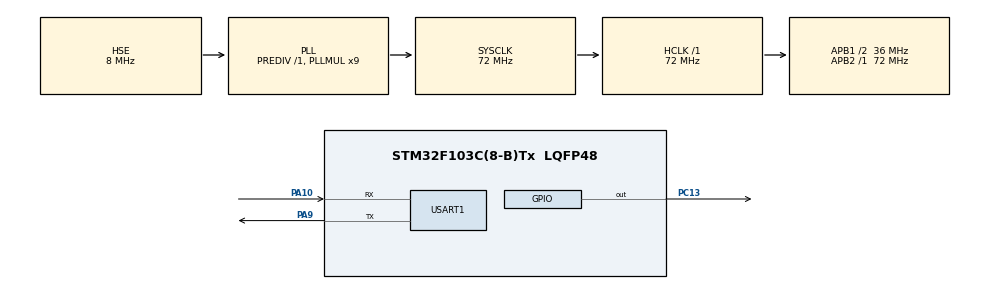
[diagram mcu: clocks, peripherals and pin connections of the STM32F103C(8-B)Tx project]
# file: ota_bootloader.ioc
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Dma.Request0=USART1_RX
Dma.Request1=USART1_TX
Dma.USART1_RX.0.Direction=DMA_PERIPH_TO_MEMORY
Dma.USART1_RX.0.Instance=DMA1_Channel5
Dma.USART1_RX.0.MemDataAlignment=DMA_MDATAALIGN_BYTE
Dma.USART1_RX.0.MemInc=DMA_MINC_ENABLE
Dma.USART1_RX.0.Mode=DMA_NORMAL
Dma.USART1_RX.0.PeriphDataAlignment=DMA_PDATAALIGN_BYTE
Dma.USART1_RX.0.PeriphInc=DMA_PINC_DISABLE
Dma.USART1_RX.0.Priority=DMA_PRIORITY_LOW
Dma.USART1_TX.1.Direction=DMA_MEMORY_TO_PERIPH
Dma.USART1_TX.1.Instance=DMA1_Channel4
Dma.USART1_TX.1.MemDataAlignment=DMA_MDATAALIGN_BYTE
Dma.USART1_TX.1.MemInc=DMA_MINC_ENABLE
Dma.USART1_TX.1.Mode=DMA_NORMAL
Dma.USART1_TX.1.PeriphDataAlignment=DMA_PDATAALIGN_BYTE
Dma.USART1_TX.1.PeriphInc=DMA_PINC_DISABLE
Dma.USART1_TX.1.Priority=DMA_PRIORITY_LOW
Mcu.Family=STM32F1
Mcu.Name=STM32F103C(8-B)Tx
Mcu.Package=LQFP48
NVIC.DMA1_Channel4_IRQn=true\:0\:0\:false\:false\:true\:false\:true
NVIC.DMA1_Channel5_IRQn=true\:0\:0\:false\:false\:true\:false\:true
NVIC.PriorityGroup=NVIC_PRIORITYGROUP_4
PA10.Mode=Asynchronous
PA10.Signal=USART1_RX
PA13.Mode=Serial_Wire
PA13.Signal=SYS_JTMS-SWDIO
PA14.Mode=Serial_Wire
PA14.Signal=SYS_JTCK-SWCLK
PA9.Mode=Asynchronous
PA9.Signal=USART1_TX
PC13-TAMPER-RTC.GPIO_ModeDefaultOutputPP=GPIO_MODE_OUTPUT_PP
PC13-TAMPER-RTC.GPIO_PuPd=GPIO_NOPULL
PC13-TAMPER-RTC.PinState=GPIO_PIN_SET
PC13-TAMPER-RTC.Signal=GPIO_Output
PD0-OSC_IN.Mode=HSE-External-Oscillator
PD0-OSC_IN.Signal=RCC_OSC_IN
PD1-OSC_OUT.Mode=HSE-External-Oscillator
PD1-OSC_OUT.Signal=RCC_OSC_OUT
ProjectManager.HeapSize=0x200
ProjectManager.StackSize=0x400
ProjectManager.TargetToolchain=MDK-ARM V5.27
RCC.AHBFreq_Value=72000000
RCC.APB1CLKDivider=RCC_HCLK_DIV2
RCC.APB1Freq_Value=36000000
RCC.APB1TimFreq_Value=72000000
RCC.APB2Freq_Value=72000000
RCC.APB2TimFreq_Value=72000000
RCC.HCLKFreq_Value=72000000
RCC.PLLMUL=RCC_PLL_MUL9
RCC.PLLSourceVirtual=RCC_PLLSOURCE_HSE
RCC.SYSCLKFreq_VALUE=72000000
RCC.SYSCLKSource=RCC_SYSCLKSOURCE_PLLCLK
RCC.USBFreq_Value=72000000
USART1.VirtualMode=VM_ASYNC
board=custom

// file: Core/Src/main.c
/* USER CODE BEGIN Header */
/**
  ******************************************************************************
  * @file           : main.c
  * @brief          : Main program body
  ******************************************************************************
  * @attention
  *
  * <h2><center>&copy; Copyright (c) 2021 STMicroelectronics.
  * All rights reserved.</center></h2>
  *
  * This software component is licensed by ST under BSD 3-Clause license,
  * the "License"; You may not use this file except in compliance with the
  * License. You may obtain a copy of the License at:
  *                        opensource.org/licenses/BSD-3-Clause
  *
  ******************************************************************************
  */
/* USER CODE END Header */
#include "main.h"
#include "dma.h"
#include "usart.h"
#include "gpio.h"

/* USER CODE BEGIN Includes */
#include "stdio.h"
#include "common.h"
/* USER CODE END Includes */

/* USER CODE BEGIN PD */
#define MAGIC_NUM           0xCAFEBABE
#define MISC_START          0x0800FC00
#define UPDATE_FIRMWARE     0xAAAAAAAA
#define ERASE_FIRMWARE      0xDEADBEEF
/* USER CODE END PD */

void SystemClock_Config(void);

/* USER CODE BEGIN 0 */

void BlinkLed(int n, int delayms)
{
    for (int i = 0; i < n * 2; i++) {
        HAL_GPIO_TogglePin(GPIOC, GPIO_PIN_13);
        HAL_Delay(delayms);
    }
}

int install_firmware()
{
    return 0;
}

uint32_t get_args()
{
    uint32_t PageAddr = MISC_START;
    uint32_t Data;

    Data = *(__IO uint32_t *)(PageAddr+4);
    return Data;
}

int finish_update()
{
    uint32_t PageError = 0;

    FLASH_EraseInitTypeDef My_Flash;
    HAL_FLASH_Unlock();
    My_Flash.TypeErase = FLASH_TYPEERASE_PAGES;
    My_Flash.PageAddress = MISC_START;
    My_Flash.NbPages = 1;
    HAL_FLASHEx_Erase(&My_Flash, &PageError);
    HAL_FLASH_Program(FLASH_TYPEPROGRAM_WORD, MISC_START, MAGIC_NUM);//write magic number
    HAL_FLASH_Lock();
    return 0;
}

int check_misc()
{
    uint32_t PageAddr = MISC_START;
    uint32_t PageError = 0;
    uint32_t data = MAGIC_NUM;

    data = *(__IO uint32_t *)PageAddr;
    printf("read MISC_START :%0X \n", data);

    if (data != MAGIC_NUM)
    {
        printf("check MISC magic number err \n");
        return 1;
    }

    FLASH_EraseInitTypeDef My_Flash;
    HAL_FLASH_Unlock();
    My_Flash.TypeErase = FLASH_TYPEERASE_PAGES;
    My_Flash.PageAddress = PageAddr;
    My_Flash.NbPages = 1;
    HAL_FLASHEx_Erase(&My_Flash, &PageError);
    HAL_FLASH_Program(FLASH_TYPEPROGRAM_WORD, PageAddr, data);
    HAL_FLASH_Lock();

    return 0;
}
/* USER CODE END 0 */

int main(void)
{

    /* MCU Configuration--------------------------------------------------------*/

    /* Reset of all peripherals, Initializes the Flash interface and the Systick. */
    HAL_Init();

    /* Configure the system clock */
    SystemClock_Config();

    /* Initialize all configured peripherals */
    uint32_t BootArg = 0x00000000;
    MX_GPIO_Init();
    MX_DMA_Init();
    MX_USART1_UART_Init();
    /* USER CODE BEGIN 2 */

    BlinkLed(4, 200);
    printf("*****************************\n");
    printf("*                           *\n");
    printf("*         Bootloader        *\n");
    printf("*                           *\n");
    printf("*****************************\n");
    if (check_misc() != 0){
        printf("check misc failed !\n");
    } else {
        BootArg = get_args();
    }

    printf("read misc args: 0x%0X\n", BootArg);
    switch(BootArg) {
        case 0x00000000:
            break;
        case UPDATE_FIRMWARE:
            install_firmware();
            break;
        case ERASE_FIRMWARE:
        default:
            break;
    }
    Main_Menu();
    /* USER CODE END 2 */

    /* Infinite loop */
    /* USER CODE BEGIN WHILE */
    while (1)
    {
        /*should never be here*/
        HAL_GPIO_TogglePin(GPIOC, GPIO_PIN_13);
        HAL_Delay(50);
        /* USER CODE END WHILE */

    }
}

void SystemClock_Config(void)
{
    RCC_OscInitTypeDef RCC_OscInitStruct = {0};
    RCC_ClkInitTypeDef RCC_ClkInitStruct = {0};

    /** Initializes the RCC Oscillators according to the specified parameters
    * in the RCC_OscInitTypeDef structure.
    */
    RCC_OscInitStruct.OscillatorType = RCC_OSCILLATORTYPE_HSE;
    RCC_OscInitStruct.HSEState = RCC_HSE_ON;
    RCC_OscInitStruct.HSEPredivValue = RCC_HSE_PREDIV_DIV1;
    RCC_OscInitStruct.HSIState = RCC_HSI_ON;
    RCC_OscInitStruct.PLL.PLLState = RCC_PLL_ON;
    RCC_OscInitStruct.PLL.PLLSource = RCC_PLLSOURCE_HSE;
    RCC_OscInitStruct.PLL.PLLMUL = RCC_PLL_MUL9;

    if (HAL_RCC_OscConfig(&RCC_OscInitStruct) != HAL_OK)
    {
        Error_Handler();
    }

    /** Initializes the CPU, AHB and APB buses clocks
    */
    RCC_ClkInitStruct.ClockType = RCC_CLOCKTYPE_HCLK | RCC_CLOCKTYPE_SYSCLK
                                  | RCC_CLOCKTYPE_PCLK1 | RCC_CLOCKTYPE_PCLK2;
    RCC_ClkInitStruct.SYSCLKSource = RCC_SYSCLKSOURCE_PLLCLK;
    RCC_ClkInitStruct.AHBCLKDivider = RCC_SYSCLK_DIV1;
    RCC_ClkInitStruct.APB1CLKDivider = RCC_HCLK_DIV2;
    RCC_ClkInitStruct.APB2CLKDivider = RCC_HCLK_DIV1;

    if (HAL_RCC_ClockConfig(&RCC_ClkInitStruct, FLASH_LATENCY_2) != HAL_OK)
    {
        Error_Handler();
    }
}

void Error_Handler(void)
{
    __disable_irq();
    while (1)
    {
    }
}

/************************ (C) COPYRIGHT STMicroelectronics *****END OF FILE****/
